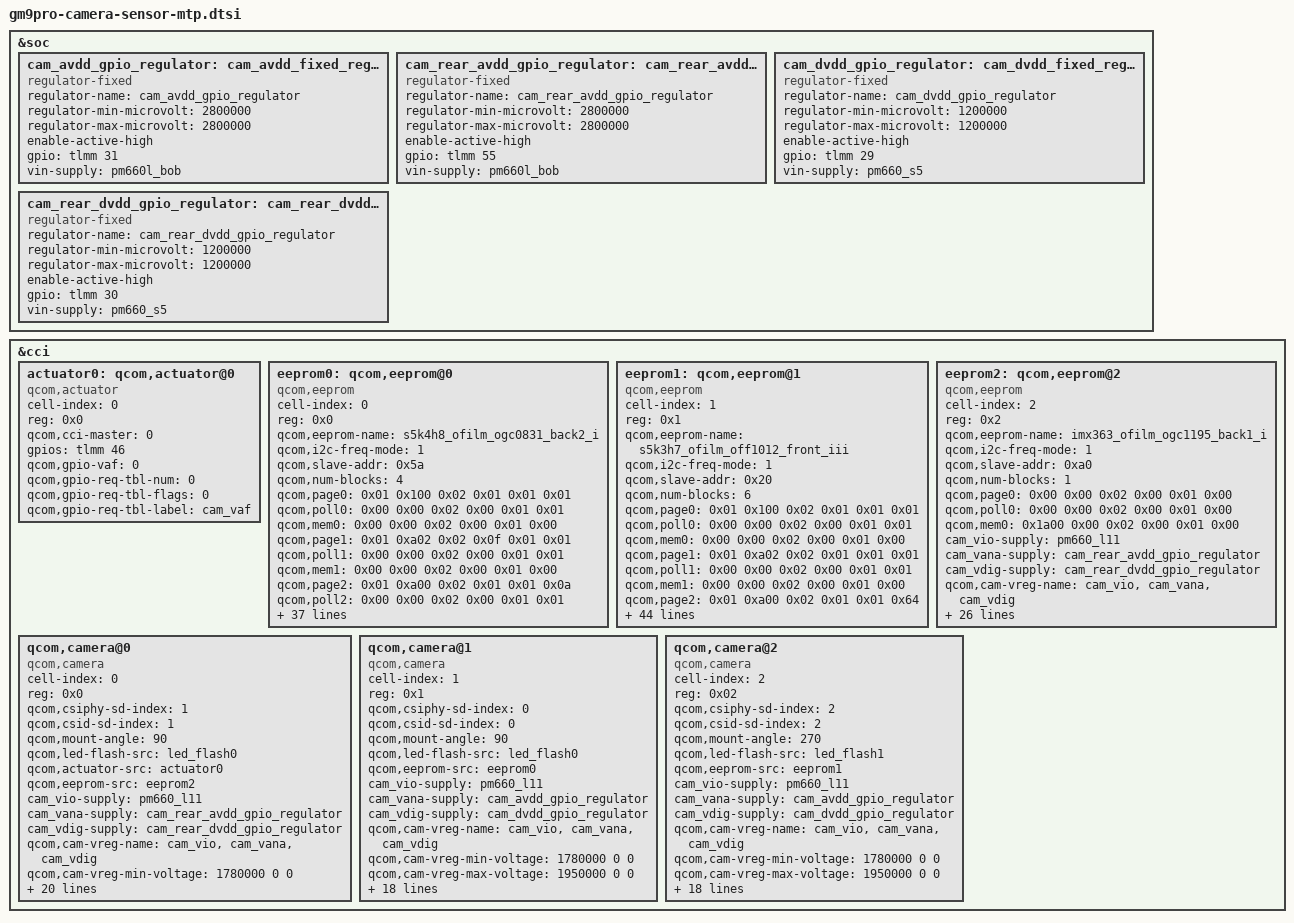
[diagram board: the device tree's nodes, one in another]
/*
 * Copyright (c) 2016-2021, The Linux Foundation. All rights reserved.
 *
 * This program is free software; you can redistribute it and/or modify
 * it under the terms of the GNU General Public License version 2 and
 * only version 2 as published by the Free Software Foundation.
 *
 * This program is distributed in the hope that it will be useful,
 * but WITHOUT ANY WARRANTY; without even the implied warranty of
 * MERCHANTABILITY or FITNESS FOR A PARTICULAR PURPOSE.  See the
 * GNU General Public License for more details.
 */

&soc {
	cam_avdd_gpio_regulator: cam_avdd_fixed_regulator {
		compatible = "regulator-fixed";
		regulator-name = "cam_avdd_gpio_regulator";
		regulator-min-microvolt = <2800000>;
		regulator-max-microvolt = <2800000>;
		enable-active-high;
		gpio = <&tlmm 31 0>;
		vin-supply = <&pm660l_bob>;
	};

	cam_rear_avdd_gpio_regulator: cam_rear_avdd_fixed_regulator {
		compatible = "regulator-fixed";
		regulator-name = "cam_rear_avdd_gpio_regulator";
		regulator-min-microvolt = <2800000>;
		regulator-max-microvolt = <2800000>;
		enable-active-high;
		gpio = <&tlmm 55 0>;
		vin-supply = <&pm660l_bob>;
	};

	cam_dvdd_gpio_regulator: cam_dvdd_fixed_regulator {
		compatible = "regulator-fixed";
		regulator-name = "cam_dvdd_gpio_regulator";
		regulator-min-microvolt = <1200000>;
		regulator-max-microvolt = <1200000>;
		enable-active-high;
		gpio = <&tlmm 29 0>;
		vin-supply = <&pm660_s5>;
	};

	cam_rear_dvdd_gpio_regulator: cam_rear_dvdd_fixed_regulator {
		compatible = "regulator-fixed";
		regulator-name = "cam_rear_dvdd_gpio_regulator";
		regulator-min-microvolt = <1200000>;
		regulator-max-microvolt = <1200000>;
		enable-active-high;
		gpio = <&tlmm 30 0>;
		vin-supply = <&pm660_s5>;
	};
};

&cci {
	/delete-node/ qcom,actuator@0;
	/delete-node/ qcom,eeprom@0;
	/delete-node/ qcom,eeprom@1;
	/delete-node/ qcom,eeprom@2;
	/delete-node/ qcom,camera@0;
	/delete-node/ qcom,camera@1;
	/delete-node/ qcom,camera@2;
	/delete-node/ qcom,camera@3;

	actuator0: qcom,actuator@0 {
		cell-index = <0>;
		reg = <0x0>;
		compatible = "qcom,actuator";
		qcom,cci-master = <0>;
		gpios = <&tlmm 46 0>;
		qcom,gpio-vaf = <0>;
		qcom,gpio-req-tbl-num = <0>;
		qcom,gpio-req-tbl-flags = <0>;
		qcom,gpio-req-tbl-label = "cam_vaf";
	};

	eeprom0: qcom,eeprom@0 {
		cell-index = <0>;
		reg = <0x0>;
		compatible = "qcom,eeprom";
		qcom,eeprom-name = "s5k4h8_ofilm_ogc0831_back2_i";
		qcom,i2c-freq-mode = <1>;
		qcom,slave-addr = <0x5a>;
		qcom,num-blocks = <4>;

		qcom,page0 = <0x01 0x100 0x02 0x01 0x01 0x01>;
		qcom,poll0 = <0x00 0x00 0x02 0x00 0x01 0x01>;
		qcom,mem0 = <0x00 0x00 0x02 0x00 0x01 0x00>;
		qcom,page1 = <0x01 0xa02 0x02 0x0f 0x01 0x01>;
		qcom,poll1 = <0x00 0x00 0x02 0x00 0x01 0x01>;
		qcom,mem1 = <0x00 0x00 0x02 0x00 0x01 0x00>;
		qcom,page2 = <0x01 0xa00 0x02 0x01 0x01 0x0a>;
		qcom,poll2 = <0x00 0x00 0x02 0x00 0x01 0x01>;
		qcom,mem2 = <0x40 0xa04 0x02 0x00 0x01 0x00>;
		qcom,page3 = <0x01 0xa00 0x02 0x00 0x01 0x01>;
		qcom,poll3 = <0x00 0x00 0x02 0x00 0x01 0x01>;
		qcom,mem3 = <0x00 0x00 0x02 0x00 0x01 0x00>;

		cam_vio-supply = <&pm660_l11>;//1.8
		cam_vana-supply = <&cam_avdd_gpio_regulator>;
		cam_vdig-supply = <&cam_dvdd_gpio_regulator>;
		qcom,cam-vreg-name = "cam_vio", "cam_vana", "cam_vdig";
		qcom,cam-vreg-min-voltage = <1780000 0 0>;
		qcom,cam-vreg-max-voltage = <1950000 0 0>;
		qcom,cam-vreg-op-mode = <105000 0 0>;
		qcom,gpio-no-mux = <0>;
		pinctrl-names = "cam_default", "cam_suspend";
		pinctrl-0 = <&cam_sensor_mclk2_active
				 &cam_sensor_rear2_active>;
		pinctrl-1 = <&cam_sensor_mclk2_suspend
				 &cam_sensor_rear2_suspend>;
		gpios = <&tlmm 34 0>,
			<&tlmm 48 0>;
		qcom,gpio-reset = <1>;
		qcom,gpio-req-tbl-num = <0 1>;
		qcom,gpio-req-tbl-flags = <1 0>;
		qcom,gpio-req-tbl-label = "CAMIF_MCLK2", "0CAM_RESET2";
		qcom,cam-power-seq-type = "sensor_gpio", "sensor_vreg", "sensor_vreg", "sensor_vreg", "sensor_clk", "sensor_gpio";
		qcom,cam-power-seq-val = "sensor_gpio_reset", "cam_vdig", "cam_vana", "cam_vio", "sensor_cam_mclk", "sensor_gpio_reset";

		qcom,cam-power-seq-cfg-val = <0 1 1 1 24000000 1>;
		qcom,cam-power-seq-delay =	  <1 1 1 0 1 18>;

		qcom,sensor-position = <0>;
		qcom,sensor-mode = <0>;
		qcom,cci-master = <1>;
		status = "ok";
		clocks = <&clock_mmss MCLK2_CLK_SRC>,
		    <&clock_mmss MMSS_CAMSS_MCLK2_CLK>;
		clock-names = "cam_src_clk", "cam_clk";
		qcom,clock-rates = <24000000 0>;
	};

	eeprom1: qcom,eeprom@1 {
		cell-index = <1>;
		reg = <0x1>;
		compatible = "qcom,eeprom";
		qcom,eeprom-name = "s5k3h7_ofilm_off1012_front_iii";
		qcom,i2c-freq-mode = <1>;
		qcom,slave-addr = <0x20>;
		qcom,num-blocks = <6>;

		qcom,page0 = <0x01 0x100 0x02 0x01 0x01 0x01>;
		qcom,poll0 = <0x00 0x00 0x02 0x00 0x01 0x01>;
		qcom,mem0 = <0x00 0x00 0x02 0x00 0x01 0x00>;
		qcom,page1 = <0x01 0xa02 0x02 0x01 0x01 0x01>;
		qcom,poll1 = <0x00 0x00 0x02 0x00 0x01 0x01>;
		qcom,mem1 = <0x00 0x00 0x02 0x00 0x01 0x00>;
		qcom,page2 = <0x01 0xa00 0x02 0x01 0x01 0x64>;
		qcom,poll2 = <0x00 0x00 0x02 0x00 0x01 0x01>;
		qcom,mem2 = <0x40 0xa04 0x02 0x00 0x01 0x00>;
		qcom,page3 = <0x01 0x100 0x02 0x01 0x01 0x01>;
		qcom,poll3 = <0x00 0x00 0x02 0x00 0x01 0x01>;
		qcom,mem3 = <0x00 0x00 0x02 0x00 0x01 0x00>;
		qcom,page4 = <0x01 0xa02 0x02 0x02 0x01 0x01>;
		qcom,poll4 = <0x00 0x00 0x02 0x00 0x01 0x01>;
		qcom,mem4 = <0x00 0x00 0x02 0x00 0x01 0x00>;
		qcom,page5 = <0x01 0xa00 0x02 0x01 0x01 0x64>;
		qcom,poll5 = <0x00 0x00 0x02 0x00 0x01 0x01>;
		qcom,mem5 = <0x40 0xa04 0x02 0x00 0x01 0x00>;

		cam_vio-supply = <&pm660_l11>;
		cam_vana-supply = <&cam_avdd_gpio_regulator>;
		cam_vdig-supply = <&cam_dvdd_gpio_regulator>;
		qcom,cam-vreg-name = "cam_vio", "cam_vana", "cam_vdig";
		qcom,cam-vreg-min-voltage = <1780000 0 0>;
		qcom,cam-vreg-max-voltage = <1950000 0 0>;
		qcom,cam-vreg-op-mode = <105000 0 0>;
		qcom,gpio-no-mux = <0>;
		pinctrl-names = "cam_default", "cam_suspend";
		pinctrl-0 = <&cam_sensor_mclk1_active
				 &cam_sensor_front_active>;
		pinctrl-1 = <&cam_sensor_mclk1_suspend
				 &cam_sensor_front_suspend>;
		gpios = <&tlmm 33 0>,
			<&tlmm 47 0>;
		qcom,gpio-reset = <1>;
		qcom,gpio-req-tbl-num = <0 1 >;
		qcom,gpio-req-tbl-flags = <1 0 >;
		qcom,gpio-req-tbl-label = "CAMIF_MCLK1", "CAM_RESET1";
		qcom,cam-power-seq-type = "sensor_gpio", "sensor_vreg", "sensor_vreg", "sensor_vreg", "sensor_clk", "sensor_gpio";
		qcom,cam-power-seq-val = "sensor_gpio_reset", "cam_vana", "cam_vdig", "cam_vio", "sensor_cam_mclk", "sensor_gpio_reset";
		qcom,cam-power-seq-cfg-val = <0 1 1 1 24000000 1>;
		qcom,cam-power-seq-delay =    <1 1 1 0 1 18>;

		qcom,sensor-position = <1>;
		qcom,sensor-mode = <0>;
		qcom,cci-master = <1>;
		status = "ok";
		clocks = <&clock_mmss MCLK1_CLK_SRC>,
			<&clock_mmss MMSS_CAMSS_MCLK1_CLK>;
		clock-names = "cam_src_clk", "cam_clk";
		qcom,clock-rates = <24000000 0>;
		};

	eeprom2: qcom,eeprom@2 {
		cell-index = <2>;
		reg = <0x2>;
		compatible = "qcom,eeprom";
		qcom,eeprom-name = "imx363_ofilm_ogc1195_back1_i";
		qcom,i2c-freq-mode = <1>;
		qcom,slave-addr = <0xa0>;
		qcom,num-blocks = <1>;

		qcom,page0 = <0x00 0x00 0x02 0x00 0x01 0x00>;
		qcom,poll0 = <0x00 0x00 0x02 0x00 0x01 0x00>;
		qcom,mem0 = <0x1a00 0x00 0x02 0x00 0x01 0x00>;

		cam_vio-supply = <&pm660_l11>;
		cam_vana-supply = <&cam_rear_avdd_gpio_regulator>;
		cam_vdig-supply = <&cam_rear_dvdd_gpio_regulator>;
		qcom,cam-vreg-name = "cam_vio", "cam_vana", "cam_vdig";
		qcom,cam-vreg-min-voltage = <1780000 0 0>;
		qcom,cam-vreg-max-voltage = <1950000 0 0>;
		qcom,cam-vreg-op-mode = <105000 0 0>;
		qcom,gpio-no-mux = <0>;
		pinctrl-names = "cam_default", "cam_suspend";
		pinctrl-0 = <&cam_sensor_mclk0_active
				 &cam_sensor_rear_active>;
		pinctrl-1 = <&cam_sensor_mclk0_suspend
				 &cam_sensor_rear_suspend>;
		gpios = <&tlmm 32 0>,
			<&tlmm 46 0>;
		qcom,gpio-reset = <1>;
		qcom,gpio-req-tbl-num = <0 1 >;
		qcom,gpio-req-tbl-flags = <1 0 >;
		qcom,gpio-req-tbl-label = "CAMIF_MCLK0", "CAM_RESET0";
		qcom,cam-power-seq-type = "sensor_gpio", "sensor_vreg", "sensor_vreg", "sensor_vreg", "sensor_clk", "sensor_gpio";
		qcom,cam-power-seq-val = "sensor_gpio_reset", "cam_vdig", "cam_vio", "cam_vana", "sensor_cam_mclk", "sensor_gpio_reset";
		qcom,cam-power-seq-cfg-val = <0 1 1 1 24000000 1>;
		qcom,cam-power-seq-delay =    <5 0 5 5 5 5>;

		qcom,cci-master = <0>;
		status = "ok";
		clocks = <&clock_mmss MCLK0_CLK_SRC>,
			<&clock_mmss MMSS_CAMSS_MCLK0_CLK>;
		clock-names = "cam_src_clk", "cam_clk";
		qcom,clock-rates = <24000000 0>;
		};

// imx363
	qcom,camera@0 {
		cell-index = <0>;
		compatible = "qcom,camera";
		reg = <0x0>;
		qcom,csiphy-sd-index = <1>;
		qcom,csid-sd-index = <1>;
		qcom,mount-angle = <90>;
		qcom,led-flash-src = <&led_flash0>;
		qcom,actuator-src = <&actuator0>;
		qcom,eeprom-src = <&eeprom2>;
		cam_vio-supply = <&pm660_l11>;
		cam_vana-supply = <&cam_rear_avdd_gpio_regulator>;
		cam_vdig-supply = <&cam_rear_dvdd_gpio_regulator>;
		qcom,cam-vreg-name = "cam_vio", "cam_vana", "cam_vdig";
		qcom,cam-vreg-min-voltage = <1780000 0 0>;
		qcom,cam-vreg-max-voltage = <1950000 0 0>;
		qcom,cam-vreg-op-mode = <105000 0 0>;
		qcom,gpio-no-mux = <0>;
		pinctrl-names = "cam_default", "cam_suspend";
		pinctrl-0 = <&cam_sensor_mclk0_active
				 &cam_sensor_rear_active>;
		pinctrl-1 = <&cam_sensor_mclk0_suspend
				 &cam_sensor_rear_suspend>;
		gpios = <&tlmm 32 0>,
			<&tlmm 46 0>,
            <&tlmm 28 0>;
		qcom,gpio-reset = <1>;
		qcom,gpio-vaf = <0x02>;
		qcom,gpio-req-tbl-num = <0 1 2>;
		qcom,gpio-req-tbl-flags = <1 0 0>;
		qcom,gpio-req-tbl-label = "CAMIF_MCLK0", "CAM_RESET0", "CAM_VAF";
		qcom,sensor-position = <0>;
		qcom,sensor-mode = <0>;
		qcom,cci-master = <0>;
		status = "ok";
		clocks = <&clock_mmss MCLK0_CLK_SRC>,
			<&clock_mmss MMSS_CAMSS_MCLK0_CLK>;
		clock-names = "cam_src_clk", "cam_clk";
		qcom,clock-rates = <24000000 0>;
	};

// s5k4h8
	qcom,camera@1 {
		cell-index = <1>;
		compatible = "qcom,camera";
		reg = <0x1>;
		qcom,csiphy-sd-index = <0>;
		qcom,csid-sd-index = <0>;
		qcom,mount-angle = <90>;
		qcom,led-flash-src = <&led_flash0>;
		qcom,eeprom-src = <&eeprom0>;
		cam_vio-supply = <&pm660_l11>;//1.8
		cam_vana-supply = <&cam_avdd_gpio_regulator>;
		cam_vdig-supply = <&cam_dvdd_gpio_regulator>;
		qcom,cam-vreg-name = "cam_vio", "cam_vana", "cam_vdig";
		qcom,cam-vreg-min-voltage = <1780000 0 0>;
		qcom,cam-vreg-max-voltage = <1950000 0 0>;
		qcom,cam-vreg-op-mode = <105000 0 0>;
		qcom,gpio-no-mux = <0>;
		pinctrl-names = "cam_default", "cam_suspend";
		pinctrl-0 = <&cam_sensor_mclk2_active
				 &cam_sensor_rear2_active>;
		pinctrl-1 = <&cam_sensor_mclk2_suspend
				 &cam_sensor_rear2_suspend>;
		gpios = <&tlmm 34 0>,
			<&tlmm 48 0>;
		qcom,gpio-reset = <1>;
		qcom,gpio-req-tbl-num = <0 1>;
		qcom,gpio-req-tbl-flags = <1 0>;
		qcom,gpio-req-tbl-label = "CAMIF_MCLK2", "CAM_RESET2";
		qcom,sensor-position = <0>;
		qcom,sensor-mode = <0>;
		qcom,cci-master = <1>;
		status = "ok";
		clocks = <&clock_mmss MCLK2_CLK_SRC>,
		    <&clock_mmss MMSS_CAMSS_MCLK2_CLK>;
		clock-names = "cam_src_clk", "cam_clk";
		qcom,clock-rates = <24000000 0>;
	};

// s5k3h7
	qcom,camera@2 {
		cell-index = <2>;
		compatible = "qcom,camera";
		reg = <0x02>;
		qcom,csiphy-sd-index = <2>;
		qcom,csid-sd-index = <2>;
		qcom,mount-angle = <270>;
		qcom,led-flash-src = <&led_flash1>;
		qcom,eeprom-src = <&eeprom1>;
		cam_vio-supply = <&pm660_l11>;
		cam_vana-supply = <&cam_avdd_gpio_regulator>;
		cam_vdig-supply = <&cam_dvdd_gpio_regulator>;
		qcom,cam-vreg-name = "cam_vio", "cam_vana", "cam_vdig";
		qcom,cam-vreg-min-voltage = <1780000 0 0>;
		qcom,cam-vreg-max-voltage = <1950000 0 0>;
		qcom,cam-vreg-op-mode = <105000 0 0>;
		qcom,gpio-no-mux = <0>;
		pinctrl-names = "cam_default", "cam_suspend";
		pinctrl-0 = <&cam_sensor_mclk1_active
				 &cam_sensor_front_active>;
		pinctrl-1 = <&cam_sensor_mclk1_suspend
				 &cam_sensor_front_suspend>;
		gpios = <&tlmm 33 0>,
			<&tlmm 47 0>;
		qcom,gpio-reset = <1>;
		qcom,gpio-req-tbl-num = <0 1>;
		qcom,gpio-req-tbl-flags = <1 0>;
		qcom,gpio-req-tbl-label = "CAMIF_MCLK1", "CAM_RESET1";
		qcom,sensor-position = <1>;
		qcom,sensor-mode = <0>;
		qcom,cci-master = <1>;
		status = "ok";
		clocks = <&clock_mmss MCLK1_CLK_SRC>,
			<&clock_mmss MMSS_CAMSS_MCLK1_CLK>;
		clock-names = "cam_src_clk", "cam_clk";
		qcom,clock-rates = <24000000 0>;
	};

};
